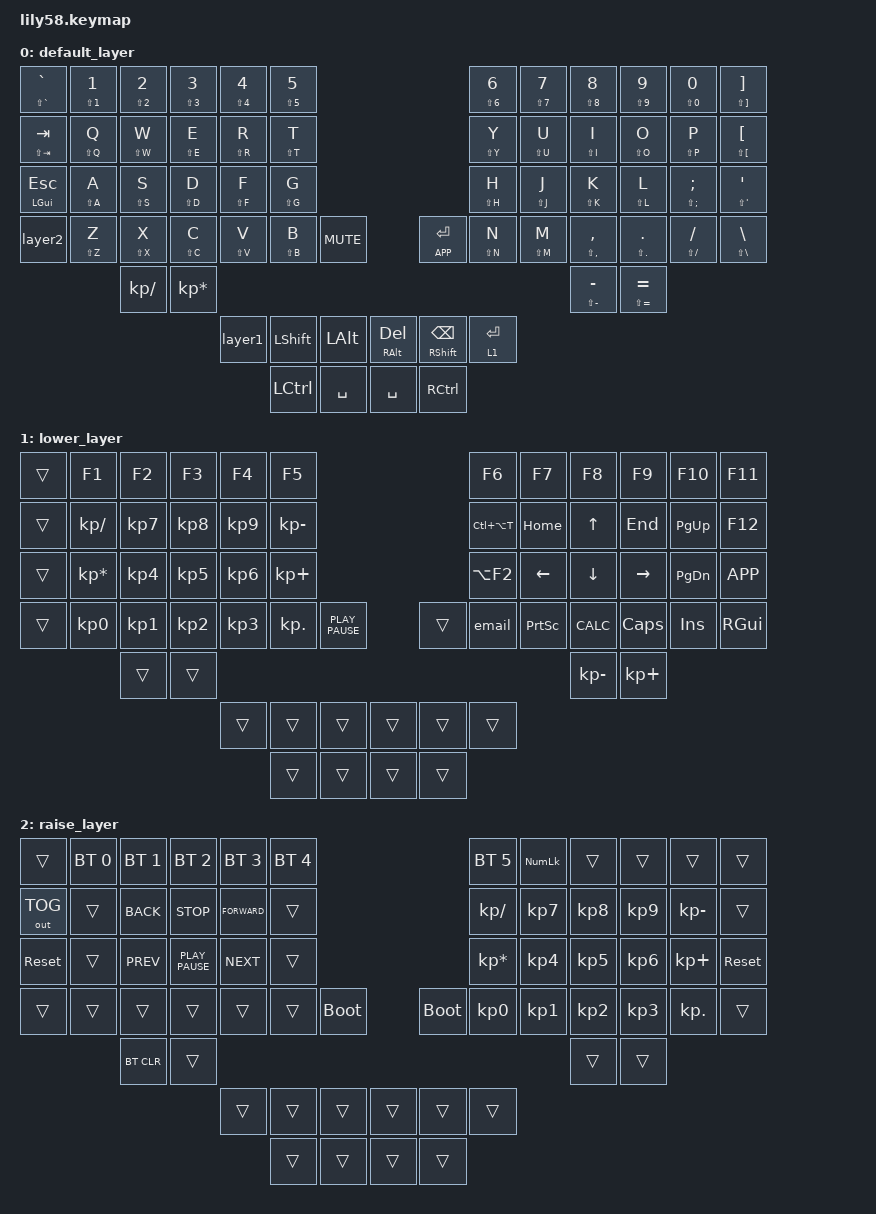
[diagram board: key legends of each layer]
/*
 * Copyright (c) 2020 The ZMK Contributors
 *
 * SPDX-License-Identifier: MIT
 */

#include <behaviors.dtsi>
#include <dt-bindings/zmk/keys.h>
#include <dt-bindings/zmk/bt.h>
#include <dt-bindings/zmk/ext_power.h>
#include <dt-bindings/zmk/outputs.h>

#define AS(keycode) &as LS(keycode) keycode     // Autoshift Macro

/ {
    behaviors {
        // hw_soft_off: hw_soft_off {
        //     compatible = "zmk,behavior-soft-off";
        //     #binding-cells = <0>;
        //     hold-time-ms = <5000>;
        // };

        as: auto_shift {
            compatible = "zmk,behavior-hold-tap";
            #binding-cells = <2>;
            tapping_term_ms = <200>;
            quick_tap_ms = <200>;
            require-prior-idle-ms = <150>;
            flavor = "tap-preferred";
            bindings = <&kp>, <&kp>;
        };

        hm: homerow_mods {
            compatible = "zmk,behavior-hold-tap";
            #binding-cells = <2>;
            tapping-term-ms = <200>;
            quick-tap-ms = <200>;
            flavor = "tap-preferred";
            bindings = <&kp>, <&kp>;
        };

        layer1: layer1 {
            compatible = "zmk,behavior-tap-dance";
            label = "LAYER1";
            #binding-cells = <0>;
            bindings = <&mo 1>, <&tog 1>;
        };

        layer2: layer2 {
            compatible = "zmk,behavior-tap-dance";
            label = "LAYER2";
            #binding-cells = <0>;
            bindings = <&mo 2>, <&tog 2>;
        };
    };

    // soft_off_behavior_key {
    //     compatible = "zmk,gpio-key-behavior-trigger";
    //     bindings = <&hw_soft_off>;
    //     key = <&wakeup_key>;
    // };

    macros {
        email: email {
            compatible = "zmk,behavior-macro";
            #binding-cells = <0>;
            bindings =
                <&macro_wait_time 20>,
                <&macro_press &kp LCTRL>, <&macro_pause_for_release>, <&macro_release &kp LCTRL>, <&macro_pause_for_release>,
                <&macro_tap &kp U &kp R &kp A &kp DOT &kp M &kp A &kp K &kp O &kp V &kp E &kp N &kp AT &kp G &kp M &kp A &kp I &kp L &kp DOT &kp C &kp O &kp M 
                &kp TAB>;

            label = "EMAIL";
            tap-ms = <20>;
        };

        downhome: downhome {
            compatible = "zmk,behavior-macro";
            #binding-cells = <0>;
            bindings =
                <&macro_tap &kp DOWN &kp HOME>;
        };

        downend: downend {
            compatible = "zmk,behavior-macro";
            #binding-cells = <0>;
            bindings =
                <&macro_tap &kp DOWN &kp END>;
        };
    };

    combos {
        compatible = "zmk,combos";

        combo_esc {
            timeout-ms = <40>;
            require-prior-idle-ms = <250>;
            key-positions = <2 3>;
            bindings = <&kp ESC>;
            layers = <0>;
        };

        combo_menu {
            timeout-ms = <40>;
            require-prior-idle-ms = <250>;
            key-positions = <8 9>;
            bindings = <&kp K_APP>;
            layers = <0>;
        };

        combo_stab {
            timeout-ms = <40>;
            require-prior-idle-ms = <250>;
            key-positions = <14 15>;
            bindings = <&kp LS(TAB)>;
            layers = <0>;
        };

        combo_tab {
            timeout-ms = <40>;
            require-prior-idle-ms = <250>;
            key-positions = <15 16>;
            bindings = <&kp TAB>;
            layers = <0>;
        };

        combo_ctrltab {
            timeout-ms = <40>;
            require-prior-idle-ms = <250>;
            key-positions = <38 39>;
            bindings = <&kp LC(TAB)>;
            layers = <0>;
        };

        combo_alttab {
            timeout-ms = <40>;
            require-prior-idle-ms = <250>;
            key-positions = <39 40>;
            bindings = <&kp LA(TAB)>;
            layers = <0>;
        };

        combo_home {
            timeout-ms = <40>;
            require-prior-idle-ms = <250>;
            key-positions = <19 20>;
            bindings = <&kp HOME>;
            layers = <0>;
        };

        combo_end {
            timeout-ms = <40>;
            require-prior-idle-ms = <250>;
            key-positions = <20 21>;
            bindings = <&kp END>;
            layers = <0>;
        };

        combo_left {
            timeout-ms = <40>;
            require-prior-idle-ms = <250>;
            key-positions = <19 32>;
            bindings = <&kp LEFT>;
            layers = <0>;
        };

        combo_right {
            timeout-ms = <40>;
            require-prior-idle-ms = <250>;
            key-positions = <21 32>;
            bindings = <&kp RIGHT>;
            layers = <0>;
        };

        combo_up {
            timeout-ms = <40>;
            require-prior-idle-ms = <250>;
            key-positions = <31 20>;
            bindings = <&kp UP>;
            layers = <0>;
        };

        combo_down {
            timeout-ms = <40>;
            require-prior-idle-ms = <250>;
            key-positions = <31 46>;
            bindings = <&kp DOWN>;
            layers = <0>;
        };

        combo_pgup {
            timeout-ms = <40>;
            require-prior-idle-ms = <250>;
            key-positions = <33 20>;
            bindings = <&kp PG_UP>;
            layers = <0>;
        };

        combo_pgdn {
            timeout-ms = <40>;
            require-prior-idle-ms = <250>;
            key-positions = <33 46>;
            bindings = <&kp PG_DN>;
            layers = <0>;
        };

        combo_downhome {
            timeout-ms = <40>;
            require-prior-idle-ms = <250>;
            key-positions = <45 32>;
            bindings = <&downhome>;
            layers = <0>;
        };

        combo_downend {
            timeout-ms = <40>;
            require-prior-idle-ms = <250>;
            key-positions = <47 32>;
            bindings = <&downend>;
            layers = <0>;
        };
    };
  
    keymap {
        compatible = "zmk,keymap";

        default_layer {
// ------------------------------------------------------------------------------------------------------------
// |  ESC  |  1  |  2  |  3   |  4   |  5   |                   |  6   |  7    |  8    |  9   |   0   |   `   |
// |  TAB  |  Q  |  W  |  E   |  R   |  T   |                   |  Y   |  U    |  I    |  O   |   P   |   -   |
// |  CTRL |  A  |  S  |  D   |  F   |  G   |                   |  H   |  J    |  K    |  L   |   ;   |   '   |
// | SHIFT |  Z  |  X  |  C   |  V   |  B   |   "["  |  |  "]"  |  N   |  M    |  ,    |  .   |   /   | SHIFT |
//                     | ALT  | GUI  | LOWER|  SPACE |  | ENTER | RAISE| BSPC  | GUI   |
//             bindings = <
// AS(GRAVE)    AS(N1) AS(N2) AS(N3) AS(N4) AS(N5)                               AS(N6) AS(N7) AS(   N8) AS( N9) AS(  N0) AS(RBKT)
// AS(  TAB)    AS( Q) AS( W) AS( E) AS( R) AS( T)                               AS( Y) AS( U) AS(    I) AS(  O) AS(   P) AS(LBKT)
// &mt LGUI ESC AS( A) AS( S) AS( D) AS( F) AS( G)                               AS( H) AS( J) AS(    K) AS(  L) AS(SEMI) AS( SQT)
// &layer2      AS( Z) AS( X) AS( C) AS( V) AS( B) &kp K_MUTE    &hm K_APP ENTER AS( N) AS( M) AS(COMMA) AS(DOT) AS(FSLH) AS(BSLH)
//         &kp KP_DIVIDE  &kp KP_MULTIPLY                                                          AS(MINUS) AS(EQUAL)
//                              &layer1 &kp LSHFT &kp LALT               &hm RALT DEL &hm RSHFT BSPC &lt 1 ENTER
//                                     &kp LCTRL &kp SPACE              &kp SPACE &kp RCTRL
//             >;

            bindings = <
&as LS(GRAVE) GRAVE  &as LS(N1) N1  &as LS(N2) N2  &as LS(N3) N3  &as LS(N4) N4  &as LS(N5) N5  &as LS(N6) N6  &as LS(N7) N7  &as LS(N8) N8  &as LS(N9) N9  &as LS(N0) N0  &as LS(RBKT) RBKT  &as LS(TAB) TAB  &as LS(Q) Q  &as LS(W) W  &as LS(E) E  &as LS(R) R  &as LS(T) T  &as LS(Y) Y  &as LS(U) U  &as LS(I) I  &as LS(O) O  &as LS(P) P  &as LS(LBKT) LBKT  &hm LGUI ESC  &as LS(A) A  &as LS(S) S  &as LS(D) D  &as LS(F) F  &as LS(G) G  &as LS(H) H  &as LS(J) J  &as LS(K) K  &as LS(L) L  &as LS(SEMI) SEMI  &as LS(SQT) SQT  &layer2  &as LS(Z) Z  &as LS(X) X  &as LS(C) C  &as LS(V) V  &as LS(B) B  &kp K_MUTE  &hm K_APP ENTER  &as LS(N) N  &as LS(M) M  &as LS(COMMA) COMMA  &as LS(DOT) DOT  &as LS(FSLH) FSLH  &as LS(BSLH) BSLH  &kp KP_DIVIDE  &kp KP_MULTIPLY  &as LS(MINUS) MINUS  &as LS(EQUAL) EQUAL  &layer1  &kp LSHFT  &kp LALT  &hm RALT DEL  &hm RSHFT BSPC  &lt 1 ENTER  &kp LCTRL  &kp SPACE  &kp SPACE  &kp RCTRL
            >;

            sensor-bindings = <&inc_dec_kp C_VOL_UP C_VOL_DN &inc_dec_kp UP DOWN>;
        };

        lower_layer {
// ------------------------------------------------------------------------------------------------------------
// | BTCLR | BT1 | BT2 |  BT3 |  BT4 |  BT5 |                   |      |       |       |      |       |       |
// |  F1   |  F2 |  F3 |  F4  |  F5  |  F6  |                   |  F7  |  F8   |  F9   |  F10 |  F11  |  F12  |
// |   `   |  !  |  @  |  #   |  $   |  %   |                   |  ^   |  &    |  *    |  (   |   )   |   ~   |
// |       |     |     |      |      |      |        |  |       |      |  _    |  +    |  {   |   }   |  "|"  |
//                     |      |      |      |        |  |       |      |       |       |
            bindings = <
&trans &kp F1          &kp F2    &kp F3    &kp F4     &kp F5                                  &kp F6        &kp F7    &kp F8     &kp F9    &kp F10   &kp F11
&trans &kp KP_DIVIDE   &kp KP_N7 &kp KP_N8 &kp KP_N9  &kp KP_MINUS                            &kp LC(LA(T)) &kp HOME  &kp UP     &kp END   &kp PG_UP &kp F12
&trans &kp KP_MULTIPLY &kp KP_N4 &kp KP_N5 &kp KP_N6  &kp KP_PLUS                             &kp LA(F2)    &kp LEFT  &kp DOWN   &kp RIGHT &kp PG_DN &kp K_APP
&trans &kp KP_N0       &kp KP_N1 &kp KP_N2 &kp KP_N3  &kp KP_DOT   &kp K_PLAY_PAUSE    &trans &email        &kp PSCRN &kp K_CALC &kp CAPS  &kp INS   &kp RGUI
                    &trans  &trans                                                                              &kp KP_MINUS &kp KP_PLUS
                                              &trans &trans &trans             &trans &trans &trans
                                                     &trans &trans             &trans &trans
            >;

            sensor-bindings = 
                <&inc_dec_kp K_PREV K_NEXT &inc_dec_kp PG_UP PG_DN>
                ;
        };

        raise_layer {
// ------------------------------------------------------------------------------------------------------------
// |       |     |     |      |      |      |                   |      |       |       |      |       |       |
// |   `   |  1  |  2  |  3   |  4   |  5   |                   |  6   |   7   |   8   |  9   |   0   |       |
// |   F1  |  F2 |  F3 |  F4  |  F5  |  F6  |                   |      |   <-  |   v   |  ^   |  ->   |       |
// |   F7  |  F8 |  F9 |  F10 |  F11 |  F12 |        |  |       |  +   |   -   |   =   |  [   |   ]   |   \   |
//                     |      |      |      |        |  |       |      |       |       |
            bindings = <
&trans       &bt BT_SEL 0     &bt BT_SEL 1      &bt BT_SEL 2      &bt BT_SEL 3  &bt BT_SEL 4                       &bt BT_SEL 5    &kp KP_NUMLOCK  &trans    &trans    &trans       &trans
&out OUT_TOG &trans           &kp K_BACK        &kp K_STOP        &kp K_FORWARD &trans                             &kp KP_DIVIDE   &kp KP_N7       &kp KP_N8 &kp KP_N9 &kp KP_MINUS &trans
&sys_reset   &trans           &kp K_PREV        &kp K_PLAY_PAUSE  &kp K_NEXT    &trans                             &kp KP_MULTIPLY &kp KP_N4       &kp KP_N5 &kp KP_N6 &kp KP_PLUS  &sys_reset
&trans       &trans           &trans            &trans            &trans        &trans   &bootloader   &bootloader &kp KP_N0       &kp KP_N1       &kp KP_N2 &kp KP_N3 &kp KP_DOT   &trans
                                &bt BT_CLR   &trans                                                                                   &trans &trans   
                                                          &trans &trans &trans        &trans &trans &trans
                                                          &trans &trans               &trans &trans
            >;

            sensor-bindings = 
                <&inc_dec_kp C_VOL_UP C_VOL_DN &inc_dec_kp PG_UP PG_DN>
                ;
        };
    };
};


// west build -d build/left -b nice_nano_v2 -- -DSHIELD=lily58_left
// west build -d build/right -b nice_nano_v2 -- -DSHIELD=lily58_right

// слева nine nano v2, права nice nano... 
// ***уже не актуально. почему то обе стали v2
// если надо поменять плату надо добавить ключ для очистки предыдущего компила
// west build -p -b build/.......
